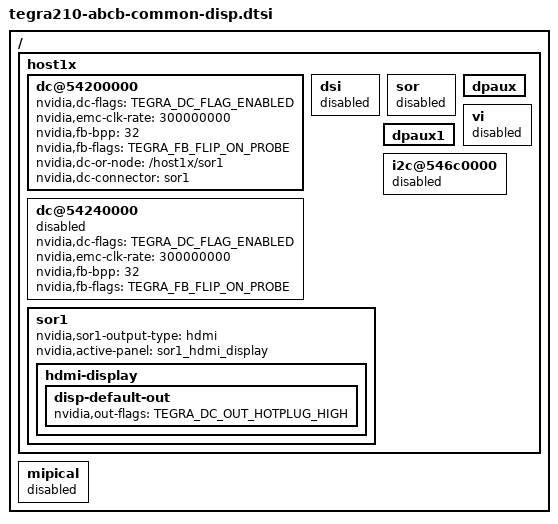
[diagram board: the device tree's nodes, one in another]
/*
 * arch/arm64/boot/dts/tegra210-abcb-common-disp.dtsi
 *
 * Copyright (c) 2016-2017, NVIDIA CORPORATION.  All rights reserved.
 *
 * This program is free software; you can redistribute it and/or modify
 * it under the terms of the GNU General Public License as published by
 * the Free Software Foundation; version 2 of the License.
 *
 * This program is distributed in the hope that it will be useful, but WITHOUT
 * ANY WARRANTY; without even the implied warranty of MERCHANTABILITY or
 * FITNESS FOR A PARTICULAR PURPOSE.  See the GNU General Public License for
 * more details.
 *
 */

#include <t210-common-platforms/tegra210-ers-hdmi-e2190-1100-a00.dtsi>

/ {
	host1x {
		/* tegradc.0 */
		dc@54200000 {
			status = "okay";
			nvidia,dc-flags = <TEGRA_DC_FLAG_ENABLED>;
			nvidia,emc-clk-rate = <300000000>;
			nvidia,fb-bpp = <32>; /* bits per pixel */
			nvidia,fb-flags = <TEGRA_FB_FLIP_ON_PROBE>;
			nvidia,dc-or-node = "/host1x/sor1";
			nvidia,dc-connector = <&sor1>;
		};

		/* tegradc.1 */
		dc@54240000 {
			status = "disabled";
			nvidia,dc-flags = <TEGRA_DC_FLAG_ENABLED>;
			nvidia,emc-clk-rate = <300000000>;
			nvidia,fb-bpp = <32>; /* bits per pixel */
			nvidia,fb-flags = <TEGRA_FB_FLIP_ON_PROBE>;
		};

		dsi {
			status = "disabled";
		};

		sor {
			status = "disabled";
		};

		dpaux {
			status = "okay";
		};

		vi {
			status = "disabled";
		};

		sor1 {
			status = "okay";
			nvidia,sor1-output-type = "hdmi";
			nvidia,active-panel = <&sor1_hdmi_display>;
			hdmi-display {
				status = "okay";
				disp-default-out {
					nvidia,out-flags = <TEGRA_DC_OUT_HOTPLUG_HIGH>;
				};
			};
		};

		dpaux1 {
			status = "okay";
		};

		i2c@546c0000 {
			status = "disabled";
		};
	};

	mipical {
		status = "disabled";
	};
};
